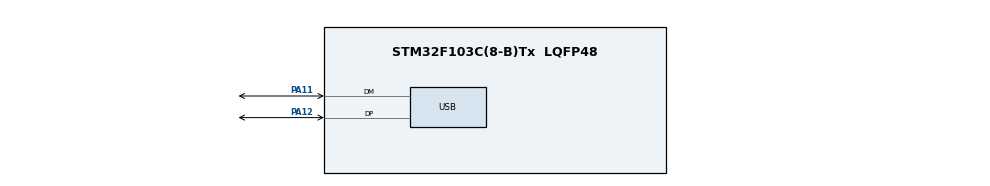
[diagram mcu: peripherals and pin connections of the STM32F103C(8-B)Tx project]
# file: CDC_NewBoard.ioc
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Mcu.Family=STM32F1
Mcu.Name=STM32F103C(8-B)Tx
Mcu.Package=LQFP48
NVIC.PriorityGroup=NVIC_PRIORITYGROUP_4
NVIC.USB_LP_CAN1_RX0_IRQn=true\:0\:0\:false\:false\:true\:false\:true
PA11.Mode=Device
PA11.Signal=USB_DM
PA12.Mode=Device
PA12.Signal=USB_DP
PA13.Mode=Serial_Wire
PA13.Signal=SYS_JTMS-SWDIO
PA14.Mode=Serial_Wire
PA14.Signal=SYS_JTCK-SWCLK
PC14-OSC32_IN.Mode=LSE-External-Oscillator
PC14-OSC32_IN.Signal=RCC_OSC32_IN
PC15-OSC32_OUT.Mode=LSE-External-Oscillator
PC15-OSC32_OUT.Signal=RCC_OSC32_OUT
PD0-OSC_IN.Mode=HSE-External-Oscillator
PD0-OSC_IN.Signal=RCC_OSC_IN
PD1-OSC_OUT.Mode=HSE-External-Oscillator
PD1-OSC_OUT.Signal=RCC_OSC_OUT
ProjectManager.HeapSize=0x200
ProjectManager.StackSize=0x400
ProjectManager.TargetToolchain=EWARM V8.32
RCC.AHBFreq_Value=72000000
RCC.APB1CLKDivider=RCC_HCLK_DIV2
RCC.APB1Freq_Value=36000000
RCC.APB1TimFreq_Value=72000000
RCC.APB2CLKDivider=RCC_HCLK_DIV2
RCC.APB2Freq_Value=36000000
RCC.APB2TimFreq_Value=72000000
RCC.HCLKFreq_Value=72000000
RCC.HSEDivPLL=RCC_HSE_PREDIV_DIV2
RCC.HSE_VALUE=16000000
RCC.PLLMUL=RCC_PLL_MUL9
RCC.RTCClockSelection=RCC_RTCCLKSOURCE_LSE
RCC.SYSCLKFreq_VALUE=72000000
RCC.SYSCLKSource=RCC_SYSCLKSOURCE_PLLCLK
RCC.USBFreq_Value=48000000
RCC.USBPrescaler=RCC_USBCLKSOURCE_PLL_DIV1_5
USB_DEVICE.CLASS_NAME_FS=CDC
USB_DEVICE.VirtualMode=Cdc
USB_DEVICE.VirtualModeFS=Cdc_FS
VP_RTC_VS_RTC_Activate.Mode=RTC_Enabled
VP_USB_DEVICE_VS_USB_DEVICE_CDC_FS.Mode=CDC_FS
board=custom

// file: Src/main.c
/* USER CODE BEGIN Header */
/**
  ******************************************************************************
  * @file           : main.c
  * @brief          : Main program body
  ******************************************************************************
  * @attention
  *
  * <h2><center>&copy; Copyright (c) 2019 STMicroelectronics.
  * All rights reserved.</center></h2>
  *
  * This software component is licensed by ST under Ultimate Liberty license
  * SLA0044, the "License"; You may not use this file except in compliance with
  * the License. You may obtain a copy of the License at:
  *                             www.st.com/SLA0044
  *
  ******************************************************************************
  */
/* USER CODE END Header */

#include "main.h"
#include "usb_device.h"

/* USER CODE BEGIN Includes */
#include "usbd_cdc_if.h"
/* USER CODE END Includes */

/* USER CODE BEGIN PV */
uint8_t Buf[20] = "Amit Chaudhary\n\r"; // len - 16

/* USER CODE END PV */

void SystemClock_Config(void);
static void MX_GPIO_Init(void);
static void MX_RTC_Init(void);
/* USER CODE BEGIN PFP */
uint32_t Debug_Write(uint8_t* buf, uint16_t len);
void Parse_Command(uint8_t *buf, uint32_t len);
void CDC_ReceiveCallback(uint8_t *buf, uint32_t len);
/* USER CODE END PFP */

int main(void)
{

  /* MCU Configuration--------------------------------------------------------*/

  /* Reset of all peripherals, Initializes the Flash interface and the Systick. */
  HAL_Init();

  /* Configure the system clock */
  SystemClock_Config();

  /* Initialize all configured peripherals */
  MX_GPIO_Init();
  MX_USB_DEVICE_Init();
  MX_RTC_Init();

  /* Infinite loop */
  /* USER CODE BEGIN WHILE */
  while (1)
  {
   // Debug_Write((uint8_t*)"Amit\n\r",6);
    HAL_Delay(10);
    /* USER CODE END WHILE */

  }
}

void SystemClock_Config(void)
{
  LL_FLASH_SetLatency(LL_FLASH_LATENCY_2);

   if(LL_FLASH_GetLatency() != LL_FLASH_LATENCY_2)
  {
    Error_Handler();
  }
  LL_RCC_HSE_Enable();

   /* Wait till HSE is ready */
  while(LL_RCC_HSE_IsReady() != 1)
  {

  }
  LL_PWR_EnableBkUpAccess();
  LL_RCC_ForceBackupDomainReset();
  LL_RCC_ReleaseBackupDomainReset();
  LL_RCC_LSE_Enable();

   /* Wait till LSE is ready */
  while(LL_RCC_LSE_IsReady() != 1)
  {

  }
  LL_RCC_SetRTCClockSource(LL_RCC_RTC_CLKSOURCE_LSE);
  LL_RCC_EnableRTC();
  LL_RCC_PLL_ConfigDomain_SYS(LL_RCC_PLLSOURCE_HSE_DIV_2, LL_RCC_PLL_MUL_9);
  LL_RCC_PLL_Enable();

   /* Wait till PLL is ready */
  while(LL_RCC_PLL_IsReady() != 1)
  {

  }
  LL_RCC_SetAHBPrescaler(LL_RCC_SYSCLK_DIV_1);
  LL_RCC_SetAPB1Prescaler(LL_RCC_APB1_DIV_2);
  LL_RCC_SetAPB2Prescaler(LL_RCC_APB2_DIV_2);
  LL_RCC_SetSysClkSource(LL_RCC_SYS_CLKSOURCE_PLL);

   /* Wait till System clock is ready */
  while(LL_RCC_GetSysClkSource() != LL_RCC_SYS_CLKSOURCE_STATUS_PLL)
  {

  }
  LL_SetSystemCoreClock(72000000);
  LL_RCC_SetUSBClockSource(LL_RCC_USB_CLKSOURCE_PLL_DIV_1_5);
}

static void MX_RTC_Init(void)
{

  LL_RTC_InitTypeDef RTC_InitStruct = {0};

    LL_PWR_EnableBkUpAccess();
    /* Enable BKP CLK enable for backup registers */
    LL_APB1_GRP1_EnableClock(LL_APB1_GRP1_PERIPH_BKP);
  /* Peripheral clock enable */
  LL_RCC_EnableRTC();

  /** Initialize RTC and set the Time and Date
  */
  RTC_InitStruct.AsynchPrescaler = 0xFFFFFFFFU;
  LL_RTC_Init(RTC, &RTC_InitStruct);
  LL_RTC_SetAsynchPrescaler(RTC, 0xFFFFFFFFU);

}

static void MX_GPIO_Init(void)
{

  /* GPIO Ports Clock Enable */
  __HAL_RCC_GPIOC_CLK_ENABLE();
  __HAL_RCC_GPIOD_CLK_ENABLE();
  __HAL_RCC_GPIOA_CLK_ENABLE();

}

/* USER CODE BEGIN 4 */

void CDC_ReceiveCallback(uint8_t *buf, uint32_t len)
{
  Parse_Command(buf,len);
}

void Parse_Command(uint8_t *buf, uint32_t len)
{
  if(buf == NULL || len ==0 ) return;

  switch(buf[0])
  {
  case 'A': Debug_Write("Amit\n\r",6); break;
  case 'a': Debug_Write("Avni\n\r",6); break;
  case 's': Debug_Write("Shiwani\n\r",9); break;
  default:  Debug_Write("??\n\r",4); break;
  }
}

uint32_t Debug_Write(uint8_t* buf, uint16_t len)
{
  CDC_Transmit_FS(buf,len);
  return 0;
}

/* USER CODE END 4 */

void Error_Handler(void)
{
}

/************************ (C) COPYRIGHT STMicroelectronics *****END OF FILE****/
